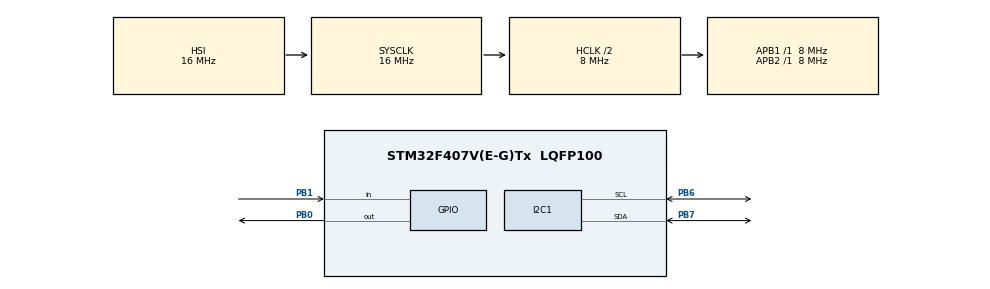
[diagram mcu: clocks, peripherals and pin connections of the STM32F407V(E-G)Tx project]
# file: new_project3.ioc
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Mcu.Family=STM32F4
Mcu.Name=STM32F407V(E-G)Tx
Mcu.Package=LQFP100
NVIC.PriorityGroup=NVIC_PRIORITYGROUP_4
PB0.Signal=GPIO_Output
PB1.Signal=GPIO_Input
PB6.Mode=I2C
PB6.Signal=I2C1_SCL
PB7.Mode=I2C
PB7.Signal=I2C1_SDA
ProjectManager.HeapSize=0x200
ProjectManager.StackSize=0x400
ProjectManager.TargetToolchain=STM32CubeIDE
RCC.AHBCLKDivider=RCC_SYSCLK_DIV2
RCC.AHBFreq_Value=8000000
RCC.APB1Freq_Value=8000000
RCC.APB1TimFreq_Value=8000000
RCC.APB2Freq_Value=8000000
RCC.APB2TimFreq_Value=8000000
RCC.CortexFreq_Value=8000000
RCC.HCLKFreq_Value=8000000
RCC.HSE_VALUE=25000000
RCC.HSI_VALUE=16000000
RCC.LSE_VALUE=32768
RCC.SYSCLKFreq_VALUE=16000000
RCC.VCOOutputFreq_Value=192000000
TIM2.Period=65535
TIM2.Prescaler=15
VP_TIM2_VS_ClockSourceINT.Mode=Internal
board=custom

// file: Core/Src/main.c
/* USER CODE BEGIN Header */
/**
  ******************************************************************************
  * @file           : main.c
  * @brief          : Main program body
  ******************************************************************************
  * @attention
  *
  * Copyright (c) 2025 STMicroelectronics.
  * All rights reserved.
  *
  * This software is licensed under terms that can be found in the LICENSE file
  * in the root directory of this software component.
  * If no LICENSE file comes with this software, it is provided AS-IS.
  *
  ******************************************************************************
  */
/* USER CODE END Header */
#include "main.h"
#include "i2c.h"
#include "tim.h"
#include "gpio.h"
#include "i2c-lcd.h"
#include "sonar.h"
#include <stdio.h>

void SystemClock_Config(void);

int main(void)
{

  /* MCU Configuration--------------------------------------------------------*/

  /* Reset of all peripherals, Initializes the Flash interface and the Systick. */
  HAL_Init();

  /* Configure the system clock */
  SystemClock_Config();

  /* Initialize all configured peripherals */
  MX_GPIO_Init();
  MX_I2C1_Init();
  MX_TIM2_Init();
  /* USER CODE BEGIN 2 */
  HAL_TIM_Base_Start(&htim2);
  HAL_Delay(50);
  lcd_init();
  HAL_Delay(100);
  lcd_clear();

  char buffer[16];
  float distance = 0.0f;
  /* USER CODE END 2 */

  /* Infinite loop */
  while (1)
  {
	  // Measure distance using the ultrasonic sensor
//	          distance = ReadSonarSensor();
//
//	          // Display distance on the LCD
//	          lcd_clear();
//	          lcd_put_cur(0, 0);
//	          lcd_send_string("Distance:");
//	          lcd_put_cur(1, 0);
//	          sprintf(buffer, "%.2f cm", distance);
//	          lcd_send_string(buffer);
//
//	          HAL_Delay(500); // Wait for 500 ms

	  // Read distance from the ultrasonic sensor
	          distance = get_median_distance();

	          // Display distance on the LCD
	          lcd_clear();
	          lcd_put_cur(0, 0);
	          lcd_send_string("Dist   :");
	              lcd_put_cur(0, 8);
	              sprintf(buffer, "%.2fcm", distance);
	              lcd_send_string(buffer);

	          HAL_Delay(300); // Wait for 300 ms
  }
}

void SystemClock_Config(void)
{
  RCC_OscInitTypeDef RCC_OscInitStruct = {0};
  RCC_ClkInitTypeDef RCC_ClkInitStruct = {0};

  /** Configure the main internal regulator output voltage
  */
  __HAL_RCC_PWR_CLK_ENABLE();
  __HAL_PWR_VOLTAGESCALING_CONFIG(PWR_REGULATOR_VOLTAGE_SCALE1);

  /** Initializes the RCC Oscillators according to the specified parameters
  * in the RCC_OscInitTypeDef structure.
  */
  RCC_OscInitStruct.OscillatorType = RCC_OSCILLATORTYPE_HSI;
  RCC_OscInitStruct.HSIState = RCC_HSI_ON;
  RCC_OscInitStruct.HSICalibrationValue = RCC_HSICALIBRATION_DEFAULT;
  RCC_OscInitStruct.PLL.PLLState = RCC_PLL_NONE;
  if (HAL_RCC_OscConfig(&RCC_OscInitStruct) != HAL_OK)
  {
    Error_Handler();
  }

  /** Initializes the CPU, AHB and APB buses clocks
  */
  RCC_ClkInitStruct.ClockType = RCC_CLOCKTYPE_HCLK|RCC_CLOCKTYPE_SYSCLK
                              |RCC_CLOCKTYPE_PCLK1|RCC_CLOCKTYPE_PCLK2;
  RCC_ClkInitStruct.SYSCLKSource = RCC_SYSCLKSOURCE_HSI;
  RCC_ClkInitStruct.AHBCLKDivider = RCC_SYSCLK_DIV2;
  RCC_ClkInitStruct.APB1CLKDivider = RCC_HCLK_DIV1;
  RCC_ClkInitStruct.APB2CLKDivider = RCC_HCLK_DIV1;

  if (HAL_RCC_ClockConfig(&RCC_ClkInitStruct, FLASH_LATENCY_0) != HAL_OK)
  {
    Error_Handler();
  }
}

void Error_Handler(void)
{
  __disable_irq();
  while (1)
  {
  }
}
